# STM32MP153 register map
File version: 1.4
CPU: CM4 r0p1, little endian, no MPU, FPU, 4 interrupt priority bits
Registers are 32-bit, read-write, reset 0x0 unless marked. A register's access mark holds for its fields unless they carry their own. Offsets are from the block's base; [hi:lo] are bit positions; {n}, {i} and the like mark numbered series.

## ETZPC
Base 0x5C007000
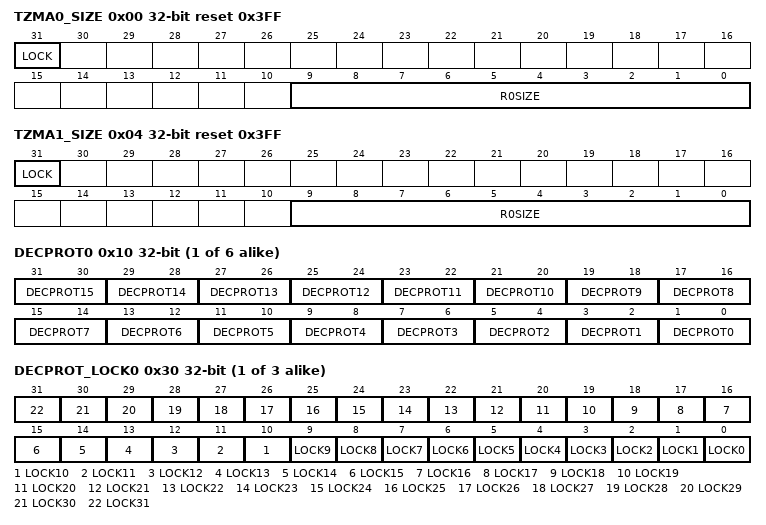
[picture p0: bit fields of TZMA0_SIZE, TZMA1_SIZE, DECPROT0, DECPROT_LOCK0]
0x00 TZMA0_SIZE reset 0x3FF — ETZPC ROM secure size definition
  [31] LOCK, [9:0] R0SIZE
0x04 TZMA1_SIZE reset 0x3FF — ETZPC RAM secure size definition
  [31] LOCK, [9:0] R0SIZE
{0x10+4i} DECPROT{i} (i=0..5) — Register reset values
  [2n+1:2n] DECPROT{n} (n=0..15)
{0x30+4i} DECPROT_LOCK{i} (i=0..2) — ETZPC decprot lock {i} register
  [n] LOCK{n} (n=0..31)
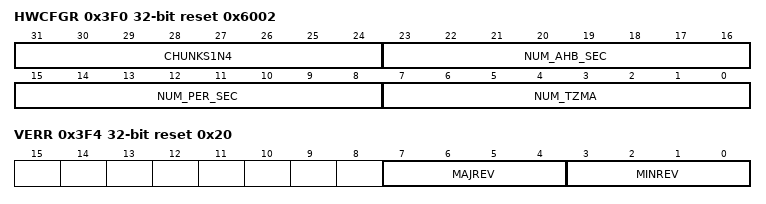
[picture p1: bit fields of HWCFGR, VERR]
0x3F0 HWCFGR ro reset 0x6002 — ETZPC IP HW configuration register
  [31:24] CHUNKS1N4, [23:16] NUM_AHB_SEC, [15:8] NUM_PER_SEC, [7:0] NUM_TZMA
0x3F4 VERR ro reset 0x20 — ETZPC IP version register
  [7:4] MAJREV, [3:0] MINREV
0x3F8 IDR ro reset 0x100061 — ETZPC IP version register
  [31:0] ID
0x3FC SIDR ro reset 0xA3C5DD01 — ETZPC IP version register
  [31:0] SID

## GICC
Base 0xA0022000
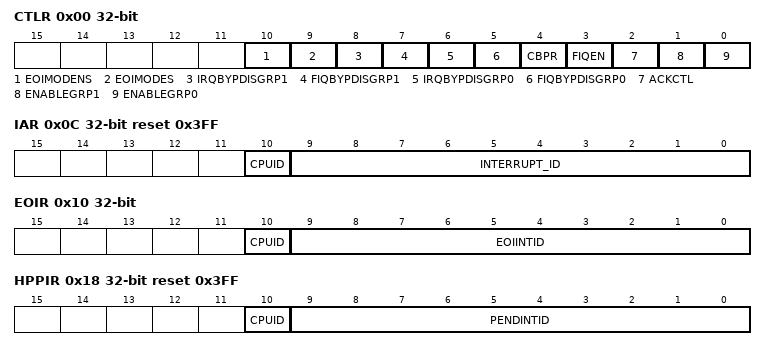
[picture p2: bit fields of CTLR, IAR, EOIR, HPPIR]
0x00 CTLR — GICC control register
  [10] EOIMODENS, [9] EOIMODES, [8] IRQBYPDISGRP1, [7] FIQBYPDISGRP1, [6] IRQBYPDISGRP0, [5] FIQBYPDISGRP0, [4] CBPR, [3] FIQEN, [2] ACKCTL, [1] ENABLEGRP1, [0] ENABLEGRP0
0x04 PMR — GICC input priority mask register
  [7:3] PRIORITY
0x08 BPR reset 0x2 — GICC binary point register
  [2:0] BINARY_POINT
0x0C IAR ro reset 0x3FF — GICC interrupt acknowledge register
  [10] CPUID, [9:0] INTERRUPT_ID
0x10 EOIR wo — GICC end of interrupt register
  [10] CPUID, [9:0] EOIINTID
0x14 RPR ro reset 0xFF — GICC running priority register
  [7:3] PRIORITY
0x18 HPPIR ro reset 0x3FF — GICC highest priority pending interrupt register
  [10] CPUID, [9:0] PENDINTID
0x1C ABPR reset 0x3 — GICC_ABPR is an alias of the non-secure GICC_BPR. When GICC_CTLR.CBPR is set to 0, a secure access to this register is equivalent to a non-secure access to GICC_BPR.
  [2:0] BINARY_POINT
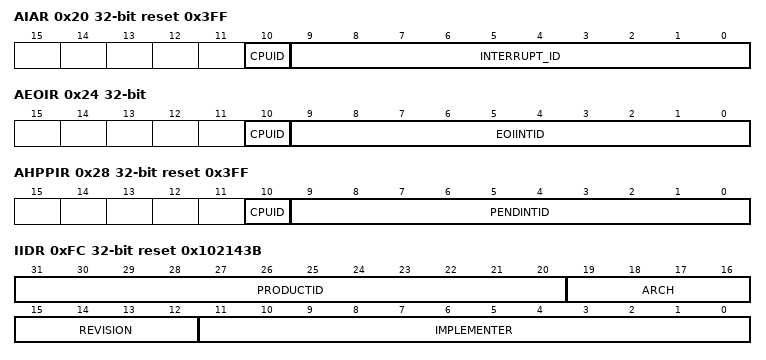
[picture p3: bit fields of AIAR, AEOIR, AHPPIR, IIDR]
0x20 AIAR ro reset 0x3FF — GICC_AIAR is an alias of the non-secure view of GICC_IAR. A secure access to this register is identical to a non-secure access to GICC_IAR.
  [10] CPUID, [9:0] INTERRUPT_ID
0x24 AEOIR wo — GICC_AEOIR is an alias of the Non-secure GICC_EOIR. A secure access to this register is similar to a non-secure access to GICC_EOIR, except that the GICC_CTLR.EOImodeS bit is used.
  [10] CPUID, [9:0] EOIINTID
0x28 AHPPIR ro reset 0x3FF — ICC_AHPPIR is an alias of the non-secure GICC_HPPIR. A secure access to this register is equivalent to a non-secure access to GICC_HPPIR.
  [10] CPUID, [9:0] PENDINTID
0xD0 APR0 — GICC active priority register
0xE0 NSAPR0 — GICC non-secure active priority register
0xFC IIDR ro reset 0x102143B — GICC interface identification register
  [31:20] PRODUCTID, [19:16] ARCH, [15:12] REVISION, [11:0] IMPLEMENTER
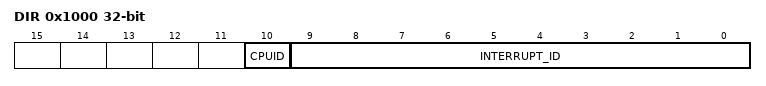
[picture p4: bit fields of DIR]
0x1000 DIR wo — GICC deactivate interrupt register
  [10] CPUID, [9:0] INTERRUPT_ID

## GICD
Base 0xA0021000
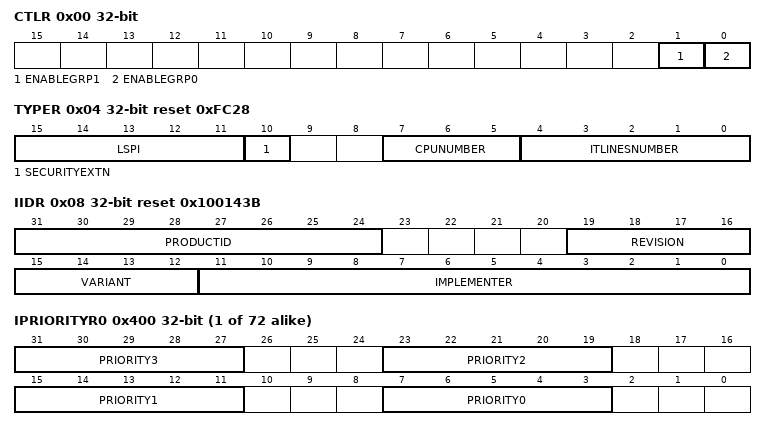
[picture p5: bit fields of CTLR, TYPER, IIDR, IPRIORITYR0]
0x00 CTLR — GICD control register
  [1] ENABLEGRP1, [0] ENABLEGRP0
0x04 TYPER ro reset 0xFC28 — GICD interrupt controller type register
  [15:11] LSPI, [10] SECURITYEXTN, [7:5] CPUNUMBER, [4:0] ITLINESNUMBER
0x08 IIDR ro reset 0x100143B — GICD implementer identification register
  [31:24] PRODUCTID, [19:16] REVISION, [15:12] VARIANT, [11:0] IMPLEMENTER
{0x80+4i} IGROUPR{i} (i=0..2) — For interrupts ID
0x8C IGROUPR3 — For interrupts ID = x*32 to ID = x*32+31
0x90 IGROUPR4 — For interrupts ID = x*32 to ID = x*32+31
{0x80+4i} IGROUPR{i} (i=5..8) — For interrupts ID
0x100 ISENABLER0 reset 0xFFFF — For interrupts ID = 0 to ID = 31
{0x100+4i} ISENABLER{i} (i=1..8) — For interrupts ID
0x180 ICENABLER0 reset 0xFFFF — For interrupts ID = 0 to ID = 31
{0x180+4i} ICENABLER{i} (i=1..8) — For interrupts ID
{0x200+4i} ISPENDR{i} (i=0..8) — For interrupts ID
{0x280+4i} ICPENDR{i} (i=0..8) — For interrupts ID
{0x300+4i} ISACTIVER{i} (i=0..8) — For interrupts ID
{0x380+4i} ICACTIVER{i} (i=0..8) — For interrupts ID
{0x400+4i} IPRIORITYR{i} (i=0..71) — GICD interrupt priority register {i}
  [8n+7:8n+3] PRIORITY{n} (n=0..3)
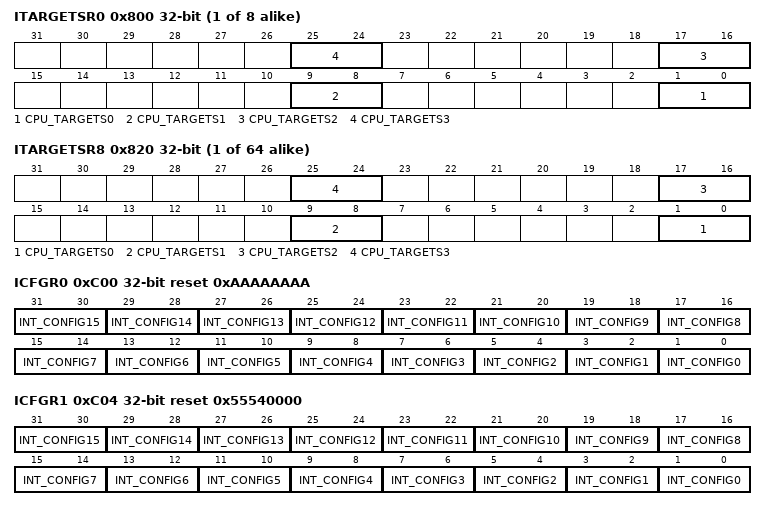
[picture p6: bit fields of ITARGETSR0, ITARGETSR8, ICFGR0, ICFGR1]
{0x800+4i} ITARGETSR{i} ro (i=0..7) — For existing SGIs and PPIs, read of CPU targets field returns the number of the processor performing the read.
  [8n+1:8n] CPU_TARGETS{n} (n=0..3)
{0x800+4i} ITARGETSR{i} (i=8..71) — GICD interrupt processor target register {i}
  [8n+1:8n] CPU_TARGETS{n} (n=0..3)
0xC00 ICFGR0 reset 0xAAAAAAAA — GICD interrupt configuration register
  [2n+1:2n] INT_CONFIG{n} (n=0..15)
0xC04 ICFGR1 reset 0x55540000 — GICD interrupt configuration register
  [2n+1:2n] INT_CONFIG{n} (n=0..15)
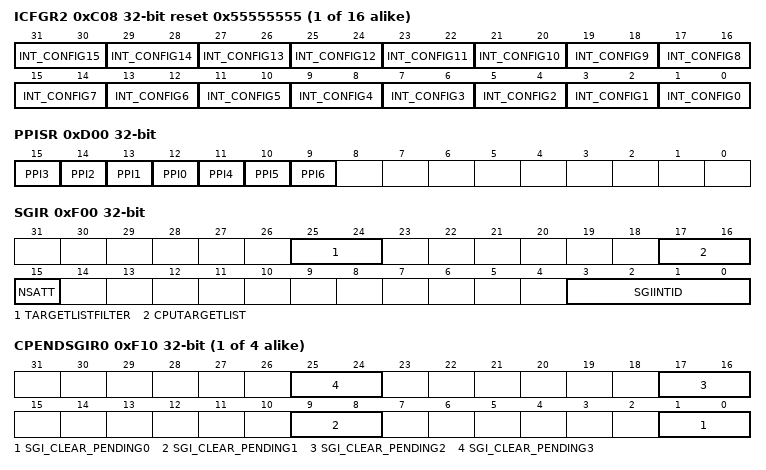
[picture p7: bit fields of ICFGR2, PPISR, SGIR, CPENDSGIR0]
{0xC00+4i} ICFGR{i} reset 0x55555555 (i=2..17) — GICD interrupt configuration register {i}
  [2n+1:2n] INT_CONFIG{n} (n=0..15)
0xD00 PPISR ro — GICD private peripheral interrupt status register
  [n+12] PPI{n} (n=0..3), [11] PPI4, [10] PPI5, [9] PPI6
0xD08 SPISR1 ro — For interrupts ID = SPI number+32, from SPI [x*32+31] to SPI [x*32]
{0xD04+4i} SPISR{i} ro (i=2..7) — For interrupts ID
0xF00 SGIR wo — GICD software generated interrupt register
  [25:24] TARGETLISTFILTER, [17:16] CPUTARGETLIST, [15] NSATT, [3:0] SGIINTID
{0xF10+4i} CPENDSGIR{i} (i=0..3) — For SGI x*4 to SGI x*4+3
  [8n+1:8n] SGI_CLEAR_PENDING{n} (n=0..3)
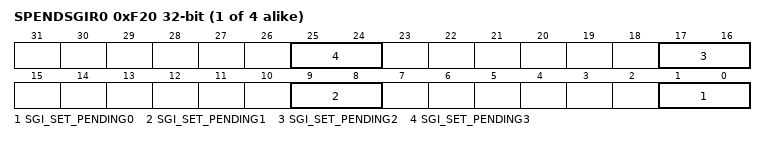
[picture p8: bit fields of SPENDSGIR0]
{0xF20+4i} SPENDSGIR{i} (i=0..3) — For SGI x*4 to SGI x*4+3
  [8n+1:8n] SGI_SET_PENDING{n} (n=0..3)
0xFD0 PIDR4 ro reset 0x4 — GICD peripheral ID4 register
{0xFC0+4i} PIDR{i} ro (i=5..7) — GICD peripheral ID5 to ID7 register {i}
0xFE0 PIDR0 ro reset 0x90 — GICD peripheral ID0 register
0xFE4 PIDR1 ro reset 0xB4 — GICD peripheral ID1 register
0xFE8 PIDR2 ro reset 0x2B — GICD peripheral ID2 register
0xFEC PIDR3 ro — GICD peripheral ID3 register
0xFF0 CIDR0 ro reset 0xD — GICD component ID0 register
0xFF4 CIDR1 ro reset 0xF0 — GICD component ID1 register
0xFF8 CIDR2 ro reset 0x5 — GICD component ID2 register
0xFFC CIDR3 ro reset 0xB1 — GICD component ID3 register
